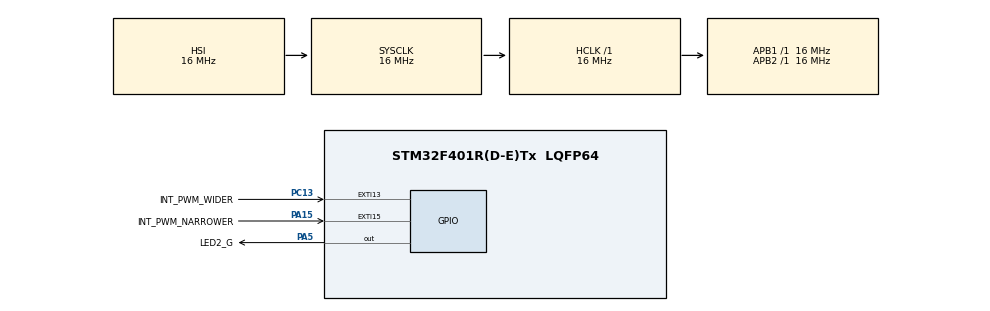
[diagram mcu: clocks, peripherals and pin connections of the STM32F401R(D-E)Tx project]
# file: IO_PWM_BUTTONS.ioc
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Mcu.Family=STM32F4
RCC.CortexFreq_Value=16000000
PC13-ANTI_TAMP.GPIO_Label=INT_PWM_WIDER
ProjectManager.StackSize=0x400
PA13.Signal=SYS_JTMS-SWDIO
PA15.GPIO_Label=INT_PWM_NARROWER
ProjectManager.TargetToolchain=STM32CubeIDE
PA15.GPIO_ModeDefaultEXTI=GPIO_MODE_IT_FALLING
RCC.LSE_VALUE=32768
RCC.AHBFreq_Value=16000000
NVIC.EXTI15_10_IRQn=true\:1\:0\:true\:false\:true\:true\:true
PA5.Signal=GPIO_Output
RCC.HSE_VALUE=25000000
board=custom
PC13-ANTI_TAMP.Signal=GPXTI13
RCC.VCOOutputFreq_Value=192000000
RCC.APB2Freq_Value=16000000
PA14.Mode=Serial_Wire
PA13.Mode=Serial_Wire
Mcu.Name=STM32F401R(D-E)Tx
RCC.SYSCLKFreq_VALUE=16000000
Mcu.Package=LQFP64
PA5.GPIO_Label=LED2_G
PC13-ANTI_TAMP.GPIO_ModeDefaultEXTI=GPIO_MODE_IT_FALLING
PA14.Signal=SYS_JTCK-SWCLK
PA15.Signal=GPXTI15
ProjectManager.HeapSize=0x200
RCC.HSI_VALUE=16000000
NVIC.PriorityGroup=NVIC_PRIORITYGROUP_4
PA15.GPIO_PuPd=GPIO_PULLUP
RCC.APB1Freq_Value=16000000

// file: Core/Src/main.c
/* USER CODE BEGIN Header */
/**
 *
 * Exercise PWM WITH GPIOs (For App Board or Breadboard)
1.Using any digital output pin, write a program which outputs a square wave, by switching the output repeatedly
 between Logic 1 and 0.
2.Change the time  of the HIGH STATE OF THE PWM with two buttons.
3.This square wave will be connected to a led which will be shine more or less.
 *
 *
 *
 *
  ******************************************************************************
  * @file           : main.c
  * @brief          : Main program body
  ******************************************************************************
  * @attention
  *
  * <h2><center>&copy; Copyright (c) 2021 STMicroelectronics.
  * All rights reserved.</center></h2>
  *
  * This software component is licensed by ST under BSD 3-Clause license,
  * the "License"; You may not use this file except in compliance with the
  * License. You may obtain a copy of the License at:
  *                        opensource.org/licenses/BSD-3-Clause
  *
  ******************************************************************************
  */
/* USER CODE END Header */
#include "main.h"
#include "gpio.h"

/* USER CODE BEGIN Includes */
/* 1. The HIGH_PWM saves the amount of time (milliseconds) that PA5 will be in the high state.
   2. It's defined volatile because I'm telling to the program that this variable may change in other part
 of the code or in another code on runtime. */
volatile uint32_t HIGH_PWM=0;

/*
 * PER_PWM is the time of PWM period and it is needed because we need make the square wave of the PWM .
 * This variable is const because it should not change.
 */
const uint32_t PER_PWM=20;
/* USER CODE END Includes */

void SystemClock_Config(void);

/* USER CODE BEGIN 0 */
//FUNCTION INTERRUP HANDLER TO INCREMENT OR DECREMENT THE FREQUENCY
void HAL_GPIO_EXTI_Callback(uint16_t GPIO_Pin)
{

	//INCREMENT THE TIME OF THE HIGH STATE
		if(INT_PWM_WIDER_Pin == GPIO_Pin && HIGH_PWM < PER_PWM)
		{
			HIGH_PWM+=1;
		}
	//DECREMENT THE TIME OF THE HIGH STATE
		// NOTE: FRE_PWM CAN'T BE NEGATIVA
		if(INT_PWM_NARROWER_Pin== GPIO_Pin &&  HIGH_PWM > 0)
		{
			HIGH_PWM-=1;
		}

}
/* USER CODE END 0 */

int main(void)
{

  /* MCU Configuration--------------------------------------------------------*/

  /* Reset of all peripherals, Initializes the Flash interface and the Systick. */
  HAL_Init();

  /* Configure the system clock */
  SystemClock_Config();

  /* Initialize all configured peripherals */
  MX_GPIO_Init();

  /* Infinite loop */
  while (1)
  {

    /* USER CODE BEGIN 3 */
	  // MAKING THE PWM WITH THE PIN PA5 OUTPUT
	  //CONDITION WHICH MAKES THE PIN A5 TO STAY IN LOW STATE IF THE TIME OF HIGH_PWM IS 0
	  if (HIGH_PWM>0)
	  {
	 HAL_GPIO_WritePin(LED2_G_GPIO_Port, LED2_G_Pin, GPIO_PIN_SET);
			 HAL_Delay(HIGH_PWM);
	  }
	  //MAKIN THE LOW STATE IN THE PIN A5
			 HAL_GPIO_WritePin(LED2_G_GPIO_Port, LED2_G_Pin, GPIO_PIN_RESET);
			 HAL_Delay((PER_PWM-HIGH_PWM));

  }
  /* USER CODE END 3 */
}

void SystemClock_Config(void)
{
  RCC_OscInitTypeDef RCC_OscInitStruct = {0};
  RCC_ClkInitTypeDef RCC_ClkInitStruct = {0};

  /** Configure the main internal regulator output voltage
  */
  __HAL_RCC_PWR_CLK_ENABLE();
  __HAL_PWR_VOLTAGESCALING_CONFIG(PWR_REGULATOR_VOLTAGE_SCALE2);
  /** Initializes the RCC Oscillators according to the specified parameters
  * in the RCC_OscInitTypeDef structure.
  */
  RCC_OscInitStruct.OscillatorType = RCC_OSCILLATORTYPE_HSI;
  RCC_OscInitStruct.HSIState = RCC_HSI_ON;
  RCC_OscInitStruct.HSICalibrationValue = RCC_HSICALIBRATION_DEFAULT;
  RCC_OscInitStruct.PLL.PLLState = RCC_PLL_NONE;
  if (HAL_RCC_OscConfig(&RCC_OscInitStruct) != HAL_OK)
  {
    Error_Handler();
  }
  /** Initializes the CPU, AHB and APB buses clocks
  */
  RCC_ClkInitStruct.ClockType = RCC_CLOCKTYPE_HCLK|RCC_CLOCKTYPE_SYSCLK
                              |RCC_CLOCKTYPE_PCLK1|RCC_CLOCKTYPE_PCLK2;
  RCC_ClkInitStruct.SYSCLKSource = RCC_SYSCLKSOURCE_HSI;
  RCC_ClkInitStruct.AHBCLKDivider = RCC_SYSCLK_DIV1;
  RCC_ClkInitStruct.APB1CLKDivider = RCC_HCLK_DIV1;
  RCC_ClkInitStruct.APB2CLKDivider = RCC_HCLK_DIV1;

  if (HAL_RCC_ClockConfig(&RCC_ClkInitStruct, FLASH_LATENCY_0) != HAL_OK)
  {
    Error_Handler();
  }
}

void Error_Handler(void)
{
  __disable_irq();
  while (1)
  {
  }
}

/************************ (C) COPYRIGHT STMicroelectronics *****END OF FILE****/
